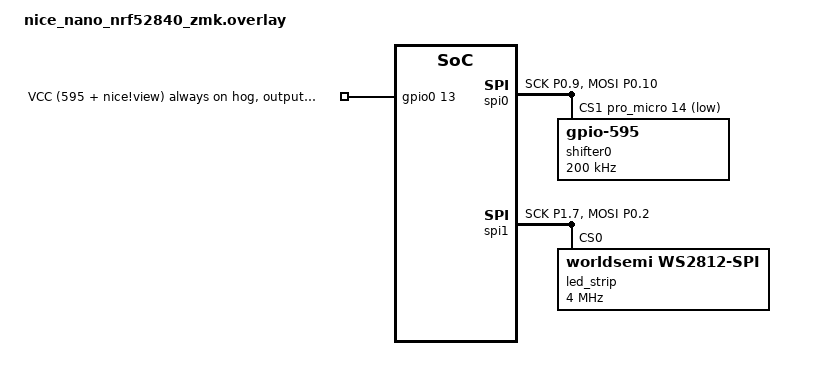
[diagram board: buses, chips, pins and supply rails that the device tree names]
/**
 * Generated by Shield Wizard for ZMK
 * Applies to part "unibody" with controller "nice_nano_v2"
 */

// pin control for spi0
// - SCK on D10
// - MOSI on D16
&pinctrl {
    /* configuration for spi0 device, default state */
    spi0_default: spi0_default {
        group1 {
            psels = <NRF_PSEL(SPIM_SCK, 0, 9)>,
                    <NRF_PSEL(SPIM_MOSI, 0, 10)>;
        };
    };
    /* configuration for spi0 device, sleep state */
    spi0_sleep: spi0_sleep {
        group1 {
            psels = <NRF_PSEL(SPIM_SCK, 0, 9)>,
                    <NRF_PSEL(SPIM_MOSI, 0, 10)>;
            low-power-enable;
        };
    };
};
&spi0 {
    compatible = "nordic,nrf-spim";
    status = "okay";
    pinctrl-0 = <&spi0_default>;
    pinctrl-1 = <&spi0_sleep>;
    pinctrl-names = "default", "sleep";
};

// devices on spi0

// CS pins for devices on spi0
&spi0 {
    cs-gpios = <&pro_micro 15 GPIO_ACTIVE_HIGH>, <&pro_micro 14 GPIO_ACTIVE_LOW>;
};

nice_view_spi: &spi0 { };

&spi0 {
    shifter0: 595@1 {
        compatible = "zmk,gpio-595";
        reg = <1>;
        status = "okay";
        gpio-controller;
        spi-max-frequency = <200000>;
        #gpio-cells = <2>;
        ngpios = <8>;
    };
};

// pin control for spi1
// - SCK on P1.07 (back pad, not connected on kerf_keeb; ws2812-spi only uses MOSI)
// - MOSI on D19
&pinctrl {
    /* configuration for spi1 device, default state */
    spi1_default: spi1_default {
        group1 {
            psels = <NRF_PSEL(SPIM_SCK, 1, 7)>,
                    <NRF_PSEL(SPIM_MOSI, 0, 2)>;
        };
    };
    /* configuration for spi1 device, sleep state */
    spi1_sleep: spi1_sleep {
        group1 {
            psels = <NRF_PSEL(SPIM_SCK, 1, 7)>,
                    <NRF_PSEL(SPIM_MOSI, 0, 2)>;
            low-power-enable;
        };
    };
};
&spi1 {
    compatible = "nordic,nrf-spim";
    status = "okay";
    pinctrl-0 = <&spi1_default>;
    pinctrl-1 = <&spi1_sleep>;
    pinctrl-names = "default", "sleep";
};

// devices on spi1

#include <dt-bindings/led/led.h>
&spi1 {
    led_strip: ws2812@0 {
        compatible = "worldsemi,ws2812-spi";
        reg = <0>;
        spi-max-frequency = <4000000>;

        chain-length = <8>;   /* LED1-LED8 underglow (bottom side) */
        spi-one-frame = <0x70>;
        spi-zero-frame = <0x40>;
        color-mapping = <LED_COLOR_ID_GREEN
                         LED_COLOR_ID_RED
                         LED_COLOR_ID_BLUE>;
    };
};
/ {
    chosen {
        zmk,underglow = &led_strip;
    };
};

/*
 * Underglow power switch (kerf_keeb PCB):
 *   D20 / P0.29 -> Q2 (2N7002 N-MOSFET) -> pulls the gate of Q1 (AO3401A P-MOSFET) low
 *   -> Q1 connects LED_VCC to B+ (battery rail, 3.0-4.2 V).
 *   R3 100k holds Q2 off during boot, R2 100k holds Q1 off, so the LEDs stay unpowered
 *   until ZMK enables them. D20 high = LEDs powered (active high).
 * - The nice!nano v2's own VCC switch (P0.13) is held on permanently with a GPIO hog,
 *   because VCC powers the 74HC595 and the nice!view. (nice!nano v2 or v2-compatible only.)
 */
/ {
    EXT_POWER {
        control-gpios = <&gpio0 29 GPIO_ACTIVE_HIGH>;
    };
};

&gpio0 {
    vcc_always_on {
        gpio-hog;
        gpios = <13 GPIO_ACTIVE_HIGH>;
        output-high;
        line-name = "VCC (595 + nice!view) always on";
    };
};
